# AE612FA0E5597LS0_CM55_HP_View register map
Vendor: Alif Semiconductor; Series: E6; File version: 1.0
CPU: CM55 r1p0, selectable endian, MPU, FPU, double-precision FPU, DSP, VTOR, 8 interrupt priority bits, 1 SAU regions
Registers are 32-bit, read-write, reset 0x0 unless marked. A register's access mark holds for its fields unless they carry their own. Offsets are from the block's base; [hi:lo] are bit positions.

## LPCPI
Base 0x43003000
Same registers: CPI 0x49030000
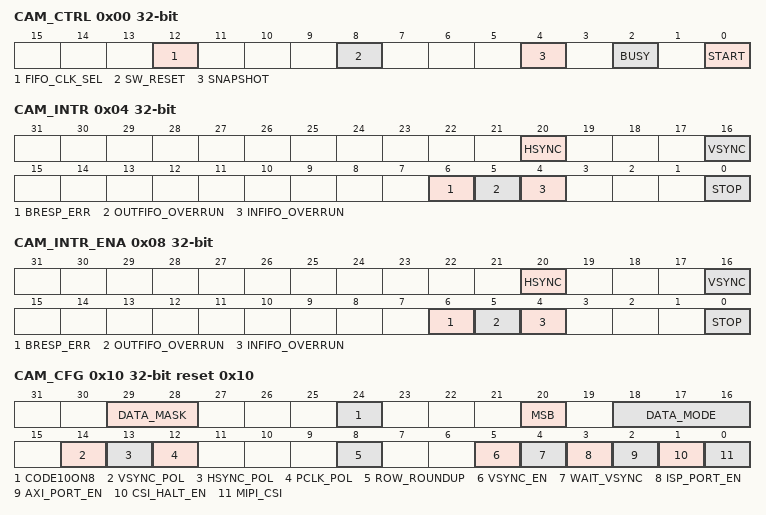
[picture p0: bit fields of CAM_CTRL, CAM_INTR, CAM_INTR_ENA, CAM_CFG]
0x00 CAM_CTRL — Camera Control Register
  [12] FIFO_CLK_SEL — Select clock source for the camera data input FIFO.
    0=Select internal clock for soft reset; 1=Select external camera clock for normal function mode
  [8] SW_RESET — Software reset. Software shall set then clear this bit.
    0=Not reset; 1=Reset
  [4] SNAPSHOT — Snapshot mode selection.
    0=Capture video data frames continuously; 1=Capture one frame then stop (snapshot mode)
  [2] BUSY ro — Status of video capture.
    0=Not capturing video; 1=Capturing video
  [0] START — Start video capture.
    0=No action; 1=Start video capture
0x04 CAM_INTR — Camera Interrupt Status Register
  [20] HSYNC wo write-1-clears — Rising edge of HSYNC signal.
  [16] VSYNC wo write-1-clears — Rising edge of VSYNC signal.
  [6] BRESP_ERR wo write-1-clears — AXI bus BRESP error.
  [5] OUTFIFO_OVERRUN wo write-1-clears — Output FIFO overrun.
  [4] INFIFO_OVERRUN wo write-1-clears — Input FIFO overrun.
  [0] STOP wo write-1-clears — Video capture stopped.
0x08 CAM_INTR_ENA — Camera Interrupt Enable Register
  [20] HSYNC — Rising edge of HSYNC signal.
  [16] VSYNC — Rising edge of VSYNC signal.
  [6] BRESP_ERR — AXI bus BRESP error.
  [5] OUTFIFO_OVERRUN — Output FIFO overrun.
  [4] INFIFO_OVERRUN — Input FIFO overrun.
  [0] STOP — Video capture stopped.
0x10 CAM_CFG reset 0x10 — Camera Configuration Register
  [29:28] DATA_MASK — Select camera data mask. Valid only when [DATA_MODE] field is set to 16-bit. Note: This register field is not functional for LPCPI.
    0=16-bit; 1=10-bit; 2=12-bit; 3=14-bit
  [24] CODE10ON8 — Special coding: transfer 10-bit coding over 8-bit data bus. Valid only when [DATA_MODE] field is set to 8-bit.
    0=Disable special 10-bit coding; 1=Enable special 10-bit coding
  [20] MSB — Select MSB/LSB Valid only when [DATA_MODE] field is set to 1-/2-/4-/8-bit.
    0=LSB; 1=MSB
  [18:16] DATA_MODE — Select video data mode.
    0=1-bit; 1=2-bit; 2=4-bit; 3=8-bit; 4=16-bit (Note: This value is not valid for LPCPI); 5=32-bit (functional only when bit [MIPI_CSI] is set to '1'); Note: This value is not valid for LPCPI; 6=64-bit (functional only when bit [MIPI_CSI] is set to '1'); Note: This value is not valid for LPCPI
  [14] VSYNC_POL — Set camera VSYNC polarity.
    0=Not invert VSYNC input; 1=Invert VSYNC input
  [13] HSYNC_POL — Set camera HSYNC polarity.
    0=Not invert HSYNC input; 1=Invert HSYNC input
  [12] PCLK_POL — Set camera PIXEL_CLK polarity.
    0=Not invert external camera PIXEL_CLK; 1=Invert external camera PIXEL_CLK
  [8] ROW_ROUNDUP — Round up pixel data to 64-bit at the end of each row.
    0=Not round up; 1=Round up pixel data to 64-bit at the end of each row
  [5] VSYNC_EN — Capture data when VSYNC is high.
    0=Capture data regardless of VSYNC status; 1=Capture data when VSYNC is high
  [4] WAIT_VSYNC — Capture video frame on the rising edge of VSYNC.
    0=Start video capture without waiting for VSYNC; 1=Start video capture on rising edge of VSYNC
  [3] ISP_PORT_EN — Enable MIPI CSI / parallel camera to ISP port.
    0=Disable ISP port; 1=Enable ISP port
  [2] AXI_PORT_EN — Enable MIPI CSI /parallel camera to AXI (system memory) port.
    0=Disable AXI port; 1=Enable AXI port
  [1] CSI_HALT_EN — Enable MIPI CSI controller halt function when FIFO is almost full. Note: This register field is not functional for LPCPI.
    0=Disable CSI IPI halt function; 1=Enable CSI IPI halt function
  [0] MIPI_CSI — Select video data source. Note: This register field is not functional for LPCPI.
    0=Select video data from parallel camera interface; 1=Select video data from MIPI CSI interface
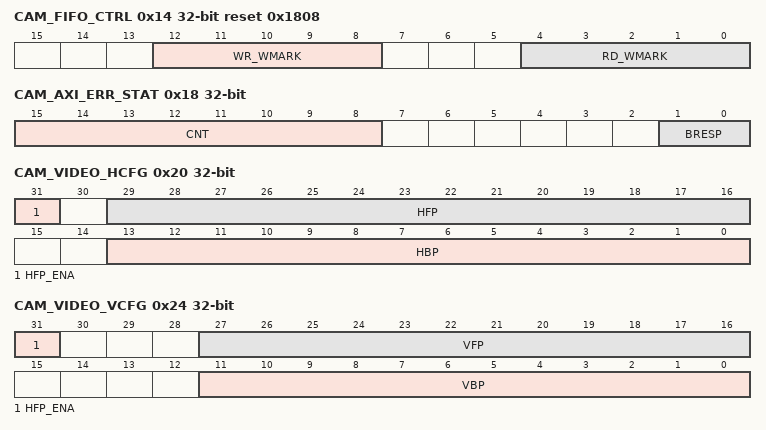
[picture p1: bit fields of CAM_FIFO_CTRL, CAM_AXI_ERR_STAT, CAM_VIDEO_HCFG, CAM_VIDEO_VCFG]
0x14 CAM_FIFO_CTRL reset 0x1808 — Camera FIFO Control Register
  [12:8] WR_WMARK — Output FIFO write watermark.
  [4:0] RD_WMARK — Output FIFO read watermark.
0x18 CAM_AXI_ERR_STAT ro — Camera AXI Error Status Register
  [15:8] CNT — AXI bus BRESP error counter.
  [1:0] BRESP — AXI bus BRESP error code.
0x20 CAM_VIDEO_HCFG — Camera Video Horizontal Configure Register
  [31] HFP_ENA — Enable horizontal cropping.
  [29:16] HFP — Horizontal Front Porch.
  [13:0] HBP — Horizontal Back Porch.
0x24 CAM_VIDEO_VCFG — Camera Video Vertical Configure Register
  [31] HFP_ENA — Enable vertical cropping.
  [27:16] VFP — Vertical Front Porch.
  [11:0] VBP — Vertical Back Porch.
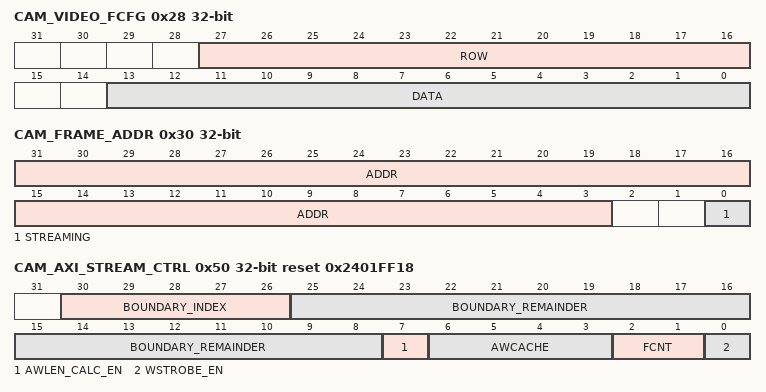
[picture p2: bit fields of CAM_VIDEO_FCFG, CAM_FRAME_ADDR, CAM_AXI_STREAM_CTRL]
0x28 CAM_VIDEO_FCFG — Camera Video Frame Configuration Register
  [27:16] ROW — Valid data rows in a frame.
  [13:0] DATA — Valid data in a row.
0x2C CAM_CSI_CMCFG — Camera MIPI CSI Color Mode Configuration Register
  [4:0] MODE — Color encoding for MIPI CSI IPI interface.
    0=IPI-16 RAW6; 1=IPI-16 RAW7; 2=IPI-16 RAW8; 3=IPI-16 RAW10; 4=IPI-16 RAW12; 5=IPI-16 RAW14; 6=IPI-16 RAW16; 7=IPI-48 RGB444; 8=IPI-48 RGB555; 9=IPI-48 RGB565; 10=IPI-48 RGB666; 11=IPI-48 XRGB888; 12=IPI-48 RGBX888; 16=IPI-16 RGB444; 17=IPI-16 RGB555; 18=IPI-16 RGB565; 19=IPI-16 RGB666; 20=IPI-16 XRGB888; 21=IPI-16 RGBX888; 22=IPI-48 RAW6; 23=IPI-48 RAW7; 24=IPI-48 RAW8; 25=IPI-48 RAW10; 26=IPI-48 RAW12
0x30 CAM_FRAME_ADDR — Camera Video Frame Start Address Register
  [31:3] ADDR — Video frame start address.
  [0] STREAMING — Video frame streaming enable.
    0=Disabled. Automatic increment of address for sequential frames.; 1=Enabled. Save sequential frames in same address range.
0x34 CAM_FRAME_ADDRB — Camera Sequential Video Frame Start Address B Register
  [31:3] ADDR — Video frame start address.
0x38 CAM_FRAME_ADDRC — Camera Sequential Video Frame Start Address C Register
  [31:3] ADDR — Video frame start address.
0x3C CAM_FRAME_ADDRD — Camera Sequential Video Frame Start Address D Register
  [31:3] ADDR — Video frame start address.
0x50 CAM_AXI_STREAM_CTRL reset 0x2401FF18 — Camera AXI Stream Control Register
  [30:26] BOUNDARY_INDEX — Next AXI AWADDR boundary index.
  [25:8] BOUNDARY_REMAINDER — How many beats to boundary.
  [7] AWLEN_CALC_EN — AXI boundary index calculator enable.
    0=Disabled; 1=Enabled
  [6:3] AWCACHE — AXI AWCACHE vector.
  [2:1] FCNT ro — Stream address counter status (clock domain crossing, quasi-static).
    0=Frame address; 1=Frame address B; 2=Frame address C; 3=Frame address D
  [0] WSTROBE_EN — Enable AXI bus write strobe.
    0=Disabled; 1=Enabled
